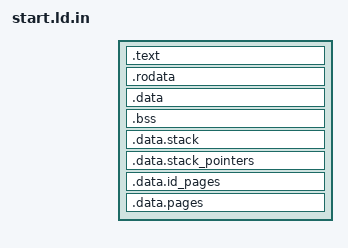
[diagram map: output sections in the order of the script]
//! AArch64 Linker Script

__page_size = (KERNEL_PAGE_SIZE * 1024);
__kernel_stack_pages = KERNEL_STACK_PAGES;
__virtual_start = KERNEL_VIRTUAL_BASE;
__kernel_start = __virtual_start + KERNEL_BASE;

ENTRY(_start)

SECTIONS
{
  . = __kernel_start;

  .text :
  {
    __text_start = .;

    KEEP(*(.text.boot))
    *(.text)

    . = ALIGN(__page_size);
    __text_end = .;
  }

  .rodata :
  {
    __rodata_start = .;

    *(.rodata)

    . = ALIGN(__page_size);
    __rodata_end = .;
  }

  .data :
  {
    __data_start = .;

    *(.data)

    . = ALIGN(__page_size);
    __data_end = .;
  }

  .bss :
  {
    __bss_start = .;

    bss = .;
    *(.bss .bss.*)

    . = ALIGN(__page_size);
    __bss_end = .;
  }
  
  __bss_size = __bss_end - __bss_start;

  // Reserve space for the primary CPU's ISR stack. Note the reversal of start
  // and end.
  .data.stack :
  {
    __kernel_stack_end = .;
    . += (__kernel_stack_pages * __page_size);
    __kernel_stack_start = .;
  }

  // Reserve space for a list of ISR stack pointers for the secondary CPU's. The
  // primary CPU will allocate the memory for the stacks and place the pointers
  // to the start of each stack in this list indexed by CPU ID.
  .data.stack_pointers :
  {
    __kernel_stack_list = .;
    . += __page_size;
  }

  __kernel_size = . - __kernel_start;

  // Reserve three pages for the kernel's temporary identity page map.
  .data.id_pages :
  {
    __kernel_id_pages_start = .;
    . += (3 * __page_size);
    __kernel_id_pages_end = .;
  }

  __kernel_id_pages_size = __kernel_id_pages_end - __kernel_id_pages_start;

  // Reserve three pages for the kernel's page tables.
  .data.pages :
  {
    __kernel_pages_start = .;
    . += (3 * __page_size);
    __kernel_pages_end = .;
  }

  __kernel_pages_size = __kernel_pages_end - __kernel_pages_start;

  __kernel_end = __kernel_pages_end;
}
